# xmc7100 register map
Vendor: Cypress Semiconductor; Series: XMC7100; File version: 1.0
CPU: CM7 r0p1, little endian, MPU, FPU, VTOR, 3 interrupt priority bits
Registers are 32-bit, read-write, reset 0x0 unless marked. A register's access mark holds for its fields unless they carry their own. Offsets are from the block's base; [hi:lo] are bit positions; {n}, {i} and the like mark numbered series; 'fields as' and 'values as' point back to an identical list.

## I2S0 — I2S registers
Base 0x40800000
Same registers: I2S1 0x40801000, I2S2 0x40802000
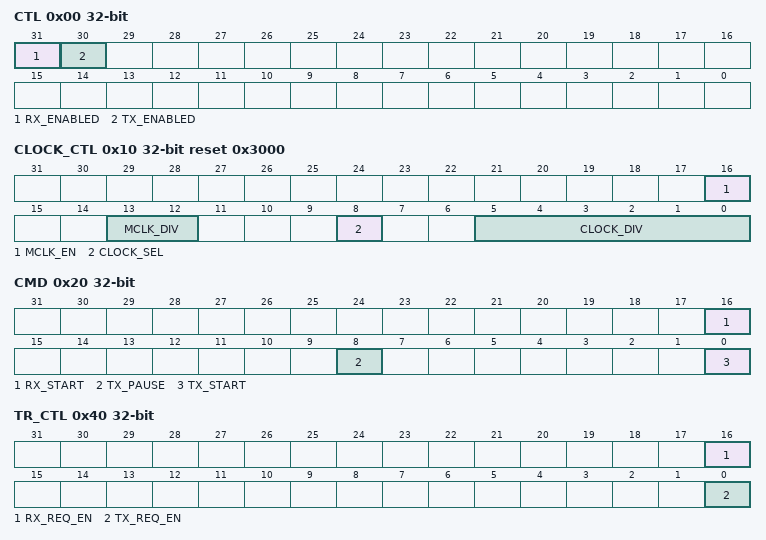
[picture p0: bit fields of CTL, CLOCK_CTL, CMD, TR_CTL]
0x00 CTL — Control
  [31] RX_ENABLED — Enables the I2S RX component: '0': Disabled. '1': Enabled.
  [30] TX_ENABLED — Enables the I2S TX component: '0': Disabled. '1': Enabled.
0x10 CLOCK_CTL reset 0x3000 — Clock control
  [16] MCLK_EN — Enable MCLK - enables MCLK divider operation Upon assertion allows MCLK Divider to begin operation. Upon de-assertion, i.e. 1-0 transition, allows MCLK divider to reach the all 0s state (reset state) then freezes the divider. This permits a controlled power-on/power-off sequence that may be used prior to going to DeepSleep/IP Disable and avoids glitching the MCLK.
  [13:12] MCLK_DIV — Selects clock divider for MCLK_OUT. CTL.TX_ENABLED=1 or CTL.RX_ENABLED=1 and and CLOCK_CTL.CLOCK_SEL=0 to enable the clock.
    0=DIV1 (Divide clk_audio_i2s by 1 (Bypass)); 1=DIV2 (Divide clk_audio_i2s by 2); 2=DIV4 (Divide clk_audio_i2s by 4); 3=DIV8 (Divide clk-audio_i2s by 8)
  [8] CLOCK_SEL — Selects clock to be used by I2S: '0': Internal clock ('clk_audio_i2s') '1': External clock ('clk_i2s_if')
  [5:0] CLOCK_DIV — Frequency divisor for generating I2S clock frequency. The selected clock with CLOCK_SEL is divided by this. '0': Bypass '1': 2 x '2': 3 x '3': 4 x ... '62': 63 x '63': 64 x
0x14 CLOCK_STAT ro — Clock Status
  [0] MCLK_DIV_OFF — MCLK Divider OFF 0: Indicates MCLK Divider not a reset state 1: Indicates MCLK Divider at reset state. This is ONLY set when IP is enabled (CTL.RX_ENABLED=1 or CTL.TX_ENABLED=1), CLOCK_CTL.MCLK_EN=0, and MCLK_DIV reaches it's reset state. The intent is that this bit indicates successful shutdown of the MCLK_DIVIDER after CLOCK_CTL.MCLK_EN transitions from 1 to 0.
0x20 CMD — Command
  [16] RX_START — Receiver enable: '0': Disabled. '1': Enabled.
  [8] TX_PAUSE — Pause enable: '0': Disabled (TX FIFO data is sent over I2S). '1': Enabled ('0' data is sent over I2S, instead of TX FIFO data).
  [0] TX_START — Transmitter enable: '0': Disabled. '1': Enabled.
0x40 TR_CTL — Trigger control
  [16] RX_REQ_EN — Trigger output ('tr_i2s_rx_req') enable for requests of DMA transfer in reception '0': Disabled. '1': Enabled.
  [0] TX_REQ_EN — Trigger output ('tr_i2s_tx_req') enable for requests of DMA transfer in transmission '0': Disabled. '1': Enabled.
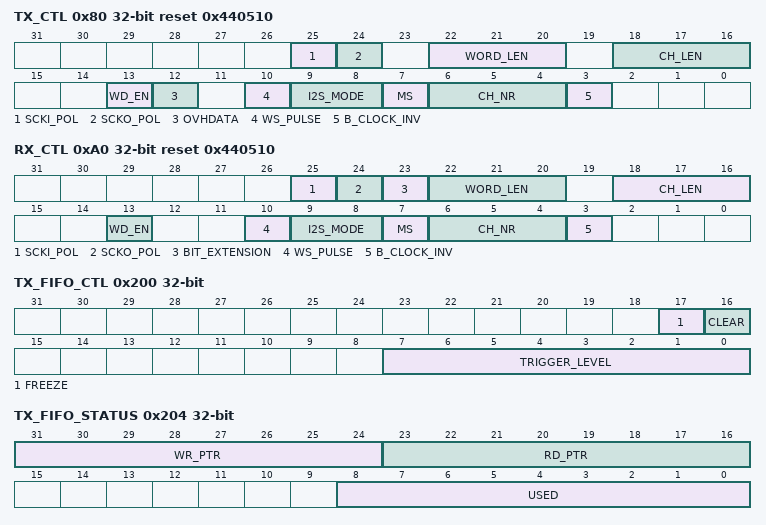
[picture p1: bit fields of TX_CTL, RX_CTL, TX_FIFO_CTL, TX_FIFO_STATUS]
0x80 TX_CTL reset 0x440510 — Transmitter control
  [25] SCKI_POL — TX slave bit clock polarity. When this bit is 1, the incoming tx_sck signal is inverted before it is received by the I2S transceiver core. This bit does not affect the internal serial data transmission timing. The word sync (TX_WS) signal is not affected by this bit setting. See TX_CTL.B_CLOCK_INV for more details.
  [24] SCKO_POL — TX master bit clock polarity. When this bit is 1, the outgoing tx_sck signal is inverted after it has been transmitted from the I2S transceiver core. This bit does not affect the internal serial data transmission timing. The word sync (TX_WS) signal is not affected by this bit setting. '0': When transmitter is in master mode, serial data is transmitted from the falling bit clock edge '1': When transmitter is in master mode, serial data is transmitted from the rising bit clock edge
  [22:20] WORD_LEN — Word length in number of bits: Note: - When this field is configured to '6' or '7', the length is set to 32-bit (same as '5'). - Don't configure this field as beyond Channel length. (Note: These bits are connected to AR38U12.TX_CFG.TX_IWL)
    0=BIT_LEN8 (8-bit); 1=BIT_LEN16 (16-bit); 2=BIT_LEN18 (18-bit); 3=BIT_LEN20 (20-bit); 4=BIT_LEN24 (24-bit); 5=BIT_LEN32 (32-bit)
  [18:16] CH_LEN — Channel length in number of bits: Note: - When this field is configured to '6' or '7', the length is set to 32-bit (same as '5'). - When TDM mode, must be 32-bit length to this field. (Note: These bits are connected to AR38U12.TX_CFG.TX_CHLEN)
    values as WORD_LEN
  [13] WD_EN — Set watchdog for 'tx_ws_in': '0': Disabled. '1': Enabled.
  [12] OVHDATA — Set overhead value: '0': Set to '0' '1': Set to '1' (Note: This bit is connected to AR38U12.TX_CFG.TX_OVHDATA)
  [10] WS_PULSE — Set WS pulse width in TDM mode: (Note: This bit is connected to AR38U12.TX_CFG.TX_WS_PULSE) Note: When not TDM mode, must be '1'.
    0=SCK_PERIOD (Pulse width is 1 SCK period); 1=CH_LENGTH (Pulse width is 1 channel length)
  [9:8] I2S_MODE — Select I2S, left-justified or TDM: (Note: These bits are connected to AR38U12.TX_CFG.TX_I2S_MODE)
    0=LEFT_JUSTIFIED; 1=I2S (I2S mode); 2=TDM_A (TDM mode A, the 1st Channel align to WSO Rising Edge); 3=TDM_B (TDM mode B, the 1st Channel align to WSO Rising edge with1 SCK Delay)
  [7] MS — Set interface in master or slave mode: (Note: This bit is connected to AR38U12.TX_CFG.TX_MS)
    0=SLAVE; 1=MASTER
  [6:4] CH_NR — Specifies number of channels per frame: Note: only '2channels' is supported during Left Justfied or I2S mode. Hence software must set '1' to this field in the modes. (Note: These bits are connected to AR38U12.TX_CFG.TX_CHSET)
    0=CH_NUM1 (1 channel); {v}=CH_NUM{v+1} ({v+1} channels) (v=1..7)
  [3] B_CLOCK_INV — Serial data transmission is advanced by 0.5 SCK cycles. This bit is valid only in TX slave mode. When set to '1', the serial data will be transmitted 0.5 SCK cycles earlier than when set to '0'. 1) TX_CTL.SCKI_POL=0 and TX_CTL.B_CLOCK_INV=0: Serial data will be transmitted off the SCK falling edge 2) TX_CTL.SCKI_POL=0 and TX_CTL.B_CLOCK_INV=1: Serial data will be transmitted off the SCK rising edge that is 0.5 SCK cycles before the SCK falling edge in 1) 3) TX_CTL.SCKI_POL=1 and TX_CTL.B_CLOCK_INV=0: Serial data will be transmitted off the SCK rising edge 4) TX_CTL.SCKI_POL=1 and TX_CTL.B_CLOCK_INV=1: Serial data will be transmitted off the SCK falling edge that is 0.5 SCK cycles before the SCK rising edge in 3) (Note that this is only the appearance w.r.t. SCK edge, the actual timing is generated by an internal clock that runs 8x the SCK frequency). The word sync (TX_WS) signal is not affected by this bit setting. Note: When Master mode, must be '0'. (Note: This bit is connected to AR38U12.TX_CFG.TX_BCLKINV)
    0=FALLING_EDGE_TX (SDO transmitted at SCK falling edge when TX_CTL.SCKI_POL=0); 1=RISING_EDGE_TX (SDO transmitted at SCK rising edge when TX_CTL.SCKI_POL=0)
0x84 TX_WATCHDOG — Transmitter watchdog
  [31:0] WD_COUNTER — Start value of the TX watchdog. With the reset value of 0x0000:0000 the counter is disabled. This is clocked by the AHB-Lite system clock 'clk_sys'.
0xA0 RX_CTL reset 0x440510 — Receiver control
  [25] SCKI_POL — RX slave bit clock polarity. When this bit is 1, the incoming rx_sck signal is inverted before it is received by the I2S receiver core. This bit does not affect the internal serial data capture timing. The word sync (RX_WS) signal is not affected by this bit setting. '0': When receiver is in slave mode, serial data is sampled on the rising bit clock edge '1': When receiver is in slave mode, serial data is sampled on the falling bit clock edge
  [24] SCKO_POL — RX master bit clock polarity. When this bit is 1, the outgoing rx_sck signal is inverted after it has been transmitted from the I2S receiver core. This bit does not affect the internal serial data capture timing. The word sync (RX_WS) signal is not affected by this bit setting.See RX_CTL.B_CLOCK_INV for more details.
  [23] BIT_EXTENSION — When reception word length is shorter than the word length of RX_FIFO_RD, extension mode of upper bit should be set. '0': Extended by '0' '1': Extended by sign bit (if MSB word is '1', then it is extended by '1', if MSB is '0' then it is extended by '0')
  [22:20] WORD_LEN — Word length in number of bits: Note: - When this field is configured to '6' or '7', the length is set to 32-bit (same as '5'). - Don't configure this field as beyond Channel length. (Note: These bits are connected to AR38U12.RX_CFG.RX_IWL)
    values as TX_CTL.WORD_LEN
  [18:16] CH_LEN — Channel length in number of bits: Note: - When this field is configured to '6' or '7', the length is set to 32-bit (same as '5'). - When TDM mode, must be 32-bit length to this field. (Note: These bits are connected to AR38U12.RX_CFG.RX_CHLEN)
    values as TX_CTL.WORD_LEN
  [13] WD_EN — Set watchdog for 'rx_ws_in' '0': Disabled. '1': Enabled.
  [10] WS_PULSE — Set WS pulse width in TDM mode: (Note: This bit is connected to AR38U12.RX_CFG.RX_WS_PULSE) Note: When not TDM mode, must be '1'.
    values as TX_CTL.WS_PULSE
  [9:8] I2S_MODE — Select I2S, left-justified or TDM: (Note: These bits are connected to AR38U12.RX_CFG.RX_I2S_MODE)
    values as TX_CTL.I2S_MODE
  [7] MS — Set interface in master or slave mode: (Note: This bit is connected to AR38U12.TX_CFG.RX_MS)
    0=SLAVE; 1=MASTER
  [6:4] CH_NR — Specifies number of channels per frame: Note: only '2channels' is supported during Left Justfied or I2S mode. Hence software must set '1' to this field in the modes. (Note: These bits are connected to AR38U12.RX_CFG.RX_CHSET)
    values as TX_CTL.CH_NR
  [3] B_CLOCK_INV — Serial data capture is delayed by 0.5 SCK cycles. This bit is valid only in RX master mode. When set to '1', the serial data will be captured 0.5 SCK cycles later than when set to '0'. 1) RX_CTL.SCKO_POL=0 and RX_CTL.B_CLOCK_INV=0: Serial data will be captured by the SCK rising edge 2) RX_CTL.SCKO_POL=0 and RX_CTL.B_CLOCK_INV=1: Serial data will be captured by the SCK falling edge that is 0.5 SCK cycles after the SCK rising edge in 1) 3) RX_CTL.SCKO_POL=1 and RX_CTL.B_CLOCK_INV=0: Serial data will be captured by the SCK falling edge 4) RX_CTL.SCKO_POL=1 and RX_CTL.B_CLOCK_INV=1: Serial data will be captured by the SCK rising edge that is 0.5 SCK cycles after the SCK falling edge in 3) (Note that this is only the appearance w.r.t. SCK edge, the actual capture timing is derived from an internal clock that runs 8x the SCK frequency). The word sync (RX_WS) signal is not affected by this bit setting. Note: When Slave mode, must be '0'. (Note: This bit is connected to AR38U12.TX_CFG.RX_BCLKINV)
    0=RISING_EDGE_RX (SDI received at SCK rising edge when RX_CTL.SCKO_POL=0); 1=FALLING_EDGE_RX (SDI received at SCK falling edge when RX_CTL.SCKO_POL=0)
0xA4 RX_WATCHDOG — Receiver watchdog
  [31:0] WD_COUNTER — Start value of the RX watchdog. With the reset value of 0x0000:0000 the counter is disabled. This is clocked by the AHB-Lite system clock 'clk_sys'.
0x200 TX_FIFO_CTL — TX FIFO control
  [17] FREEZE — When '1', hardware reads from the TX FIFO do not remove FIFO entries. Freeze will not advance the TX FIFO read pointer. This field is used only for debugging purposes.
  [16] CLEAR — When '1', the TX FIFO and TX_BUF are cleared/invalidated. Invalidation will last for as long as this field is '1'. If a quick clear/invalidation is required, the field should be set to '1' and be followed by a set to '0'. If a clear/invalidation is required for an extended time period, the field should be set to '1' during the complete time period.
  [7:0] TRIGGER_LEVEL — Trigger level. When the TX FIFO has less entries than the number of this field, a transmitter trigger event is generated.
0x204 TX_FIFO_STATUS ro
  [31:24] WR_PTR — TX FIFO write pointer: FIFO location at which a new data frame is written by the host. This field is used only for debugging purposes.
  [23:16] RD_PTR — TX FIFO read pointer: FIFO location from which a data frame is read by the hardware.This field is used only for debugging purposes.
  [8:0] USED — Number of entries in the TX FIFO. The field value is in the range [0, 256].
0x208 TX_FIFO_WR wo — TX FIFO write
  [31:0] DATA — Data written into the TX FIFO. Behavior is similar to that of a PUSH operation. Note: Don't access to this register while TX_FIFO_CTL.CLEAR is '1'.
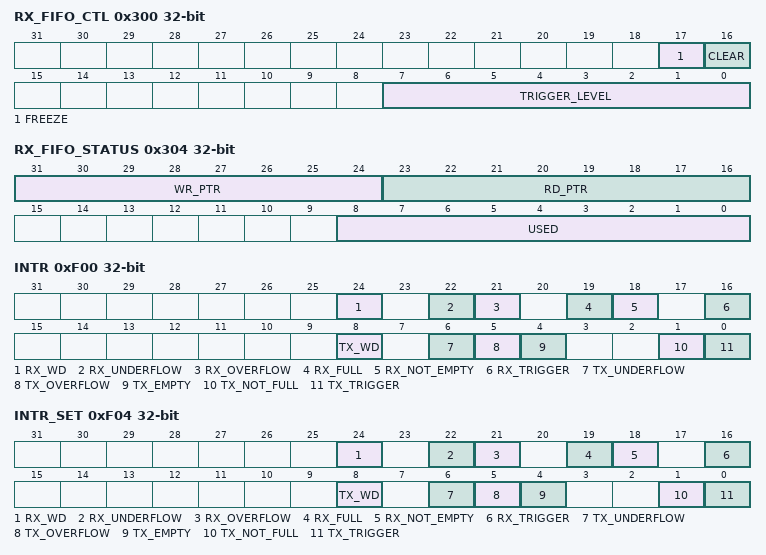
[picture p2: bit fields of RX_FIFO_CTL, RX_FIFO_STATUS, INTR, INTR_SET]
0x300 RX_FIFO_CTL — RX FIFO control
  [17] FREEZE — When '1', hardware writes to the RX FIFO have no effect. Freeze will not advance the RX FIFO write pointer. This field is used only for debugging purposee.
  [16] CLEAR — When '1', the RX FIFO and RX_BUF are cleared/invalidated. Invalidation will last for as long as this field is '1'. If a quick clear/invalidation is required, the field should be set to '1' and be followed by a set to '0'. If a clear/invalidation is required for an extended time period, the field should be set to '1' during the complete time period.
  [7:0] TRIGGER_LEVEL — Trigger level. When the RX FIFO has more entries than the number of this field, a receiver trigger event is generated. Note: software can configure up to 253 in I2S mode or Left Justified (RX_CTL.I2S_MODE = '0' or '1'). In TDM mode (RX_CTL.I2S_MODE = '2' or '3'), it can configure up to [256 - (RX_CTL.CH_NR+2)].
0x304 RX_FIFO_STATUS ro
  [31:24] WR_PTR — RX FIFO write pointer: FIFO location at which a new data frame is written by the hardware. This field is used only for debugging purposes.
  [23:16] RD_PTR — RX FIFO read pointer: FIFO location from which a data frame is read by the host. This field is used only for debugging purposes.
  [8:0] USED — Number of entries in the RX FIFO. The field value is in the range [0, 256].
0x308 RX_FIFO_RD ro — RX FIFO read
  [31:0] DATA — Data read from the RX FIFO. Reading a data frame will remove the data frame from the RX FIFO; i.e. behavior is similar to that of a POP operation. Notes: - Don't access to this register while RX_FIFO_CTL.CLEAR is '1'. - Two stored data may be not valid after CMD.RX_START is set '1'. Therefore we recommend software discard those data.
0x30C RX_FIFO_RD_SILENT ro — RX FIFO silent read
  [31:0] DATA — Data read from the RX FIFO. Reading a data frame will NOT remove the data frame from the RX FIFO; i.e. behavior is similar to that of a PEEK operation. This field is used only for debugging purposes. Notes: - Don't access to this register while RX_FIFO_CTL.CLEAR is '1'. - Two stored data may be not valid after CMD.RX_START is set '1'. Therefore we recommend software discard those data.
0xF00 INTR — Interrupt register
  [24] RX_WD — Triggers (sets to '1') when the Rx watchdog event occurs.
  [22] RX_UNDERFLOW — Attempt to read from an empty RX FIFO.
  [21] RX_OVERFLOW — Attempt to write to a full RX FIFO.
  [19] RX_FULL — RX FIFO is full.
  [18] RX_NOT_EMPTY — RX FIFO is not empty.
  [16] RX_TRIGGER — More entries in the RX FIFO than the value specified by TRIGGER_LEVEL in RX_FIFO_CTRL.
  [8] TX_WD — Triggers (sets to '1') when the Tx watchdog event occurs.
  [6] TX_UNDERFLOW — Attempt to read from an empty TX FIFO. This happens when the IP is ready to transfer data and TX_EMPTY is '1'.
  [5] TX_OVERFLOW — Attempt to write to a full TX FIFO.
  [4] TX_EMPTY — TX FIFO is empty; i.e. it has 0 entries.
  [1] TX_NOT_FULL — TX FIFO is not full.
  [0] TX_TRIGGER — Less entries in the TX FIFO than the value specified by TRIGGER_LEVEL in TX_FIFO_CTRL.
0xF04 INTR_SET — Interrupt set register
  [24] RX_WD — Write with '1' to set corresponding bit in interrupt request register.
  [22] RX_UNDERFLOW — Write with '1' to set corresponding bit in interrupt request register.
  [21] RX_OVERFLOW — Write with '1' to set corresponding bit in interrupt request register.
  [19] RX_FULL — Write with '1' to set corresponding bit in interrupt request register.
  [18] RX_NOT_EMPTY — Write with '1' to set corresponding bit in interrupt request register.
  [16] RX_TRIGGER — Write with '1' to set corresponding bit in interrupt request register.
  [8] TX_WD — Write with '1' to set corresponding bit in interrupt request register.
  [6] TX_UNDERFLOW — Write with '1' to set corresponding bit in interrupt request register.
  [5] TX_OVERFLOW — Write with '1' to set corresponding bit in interrupt request register.
  [4] TX_EMPTY — Write with '1' to set corresponding bit in interrupt request register.
  [1] TX_NOT_FULL — Write with '1' to set corresponding bit in interrupt request register.
  [0] TX_TRIGGER — Write with '1' to set corresponding bit in interrupt request register.
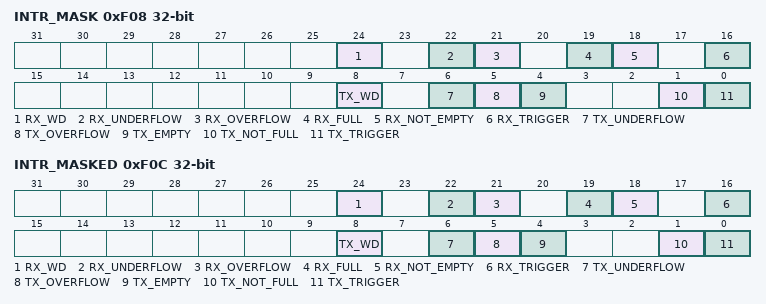
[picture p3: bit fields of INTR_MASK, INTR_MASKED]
0xF08 INTR_MASK — Interrupt mask register
  [24] RX_WD — Mask bit for corresponding bit in interrupt request register.
  [22] RX_UNDERFLOW — Mask bit for corresponding bit in interrupt request register.
  [21] RX_OVERFLOW — Mask bit for corresponding bit in interrupt request register.
  [19] RX_FULL — Mask bit for corresponding bit in interrupt request register.
  [18] RX_NOT_EMPTY — Mask bit for corresponding bit in interrupt request register.
  [16] RX_TRIGGER — Mask bit for corresponding bit in interrupt request register.
  [8] TX_WD — Mask bit for corresponding bit in interrupt request register.
  [6] TX_UNDERFLOW — Mask bit for corresponding bit in interrupt request register.
  [5] TX_OVERFLOW — Mask bit for corresponding bit in interrupt request register.
  [4] TX_EMPTY — Mask bit for corresponding bit in interrupt request register.
  [1] TX_NOT_FULL — Mask bit for corresponding bit in interrupt request register.
  [0] TX_TRIGGER — Mask bit for corresponding bit in interrupt request register.
0xF0C INTR_MASKED ro — Interrupt masked register
  [24] RX_WD — Logical and of corresponding request and mask bits.
  [22] RX_UNDERFLOW — Logical and of corresponding request and mask bits.
  [21] RX_OVERFLOW — Logical and of corresponding request and mask bits.
  [19] RX_FULL — Logical and of corresponding request and mask bits.
  [18] RX_NOT_EMPTY — Logical and of corresponding request and mask bits.
  [16] RX_TRIGGER — Logical and of corresponding request and mask bits.
  [8] TX_WD — Logical and of corresponding request and mask bits.
  [6] TX_UNDERFLOW — Logical and of corresponding request and mask bits.
  [5] TX_OVERFLOW — Logical and of corresponding request and mask bits.
  [4] TX_EMPTY — Logical and of corresponding request and mask bits.
  [1] TX_NOT_FULL — Logical and of corresponding request and mask bits.
  [0] TX_TRIGGER — Logical and of corresponding request and mask bits.

## Notices in the file
(c) (2016-2021), Cypress Semiconductor Corporation (an Infineon company)
or an affiliate of Cypress Semiconductor Corporation.
SPDX-License-Identifier: Apache-2.0
Licensed under the Apache License, Version 2.0 (the "License");
you may not use this file except in compliance with the License.
You may obtain a copy of the License at
http://www.apache.org/licenses/LICENSE-2.0
Unless required by applicable law or agreed to in writing, software
distributed under the License is distributed on an "AS IS" BASIS,
WITHOUT WARRANTIES OR CONDITIONS OF ANY KIND, either express or implied.
See the License for the specific language governing permissions and
limitations under the License.
